# dvs_reva register map
Registers are access not given, no defined reset value unless marked. A register's access mark holds for its fields unless they carry their own. Offsets are from the block's base; lines under a group give offsets from that group; [hi:lo] are bit positions; {n}, {i} and the like mark numbered series; 'fields as' and 'values as' point back to an identical list; <NAME> marks a mode.

## Memory map
0x40004800 DVS size 0x30 — Dynamic Voltage Scaling

## Interrupts
83 DVS — Dynamic Voltage Scaling Interrupt

## DVS — Dynamic Voltage Scaling
Base 0x40004800; register names take the prefix DVS_
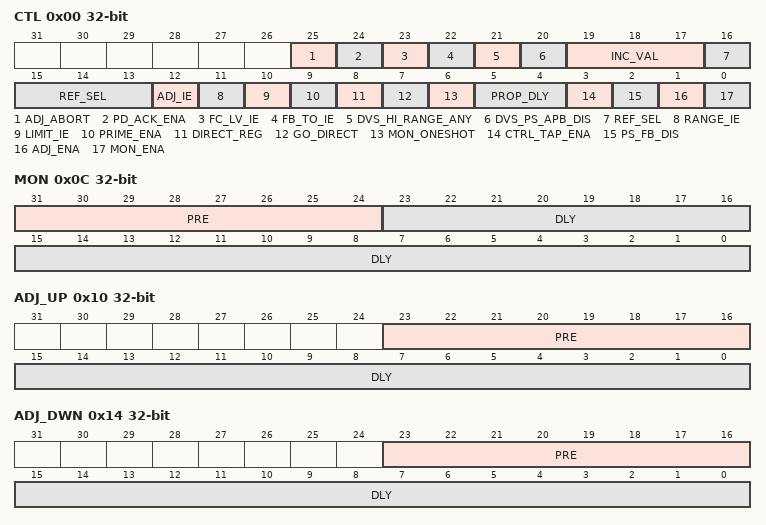
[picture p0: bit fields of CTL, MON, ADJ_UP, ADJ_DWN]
0x00 CTL — Control Register
  [25] ADJ_ABORT — Causes the DVS to enter the idle state immediately on a request to enter a low power mode
  [24] PD_ACK_ENA — Prevent DVS from ack'ing a request to enter a low power mode until in the idle state
  [23] FC_LV_IE — Enable Low Voltage Interrupt
  [22] FB_TO_IE — Enable Voltage Adjustment Timeout Interrupt
  [21] DVS_HI_RANGE_ANY — Any high range signal from a delay line will cause a voltage adjustment
  [20] DVS_PS_APB_DIS — Prevent the application code from adjusting Vcore
  [19:17] INC_VAL — Step size to increment voltage when in automatic mode
  [16:13] REF_SEL — Select TAP used for voltage adjustment
  [12] ADJ_IE — Enable Adjustment Error Interrupt
  [11] RANGE_IE — Enable Range Error Interrupt
  [10] LIMIT_IE — Enable Limit Error Interrupt
  [9] PRIME_ENA — Include a delay line priming signal before monitoring
  [8] DIRECT_REG — Step incrementally to target voltage
  [7] GO_DIRECT — Operate in automatic mode or move directly
  [6] MON_ONESHOT — Measure delay once
  [5:4] PROP_DLY — Additional delay to monitor lines
  [3] CTRL_TAP_ENA — Use the TAP Select for automatic adjustment or monitoring
  [2] PS_FB_DIS — Power Supply Feedback Disable
  [1] ADJ_ENA — Enable the power supply adjustment based on measurements
  [0] MON_ENA — Enable the DVS monitoring circuit
0x04 STAT reset 0x0 — Status Fields
  [31] FC_LV_DET_S — Interrupt flag that mirrors FC_LV_DET_INT
  [30] FC_LV_DET_INT — Interrupt flag that indicates the power supply voltage requested is below the low threshold
  [29] FB_TO_ERR_S — Interrupt flag that mirror FB_TO_ERR and is write one clear
  [28] FB_TO_ERR — Interrupt flag that indicates a timeout while adjusting the voltage
  [27] REF_SEL_ERR — Indicates the ref select register bit is out of range
  [27] REF_SEL_ERR — Indicates the ref select register bit is out of range
  [26] ADJ_ERR — Interrupt flag that indicates up and down adjustment requested simultaneously
  [25] RANGE_ERR — Interrupt flag that indicates a tap has an invalid value
  [24] LIMIT_ERR — Interrupt flag that indicates a voltage count is at/beyond manufacturer limits
  [23] VALID_TAP — At least one delay line has been enabled
  [22] HI_LIMIT_DET — Power supply voltage counter is at high limit
  [21] LO_LIMIT_DET — Power supply voltage counter is at low limit
  [20] ADJ_DLY_OK — Indicates the adjustment delay count is at 0
  [19] MON_DLY_OK — Indicates the monitor delay count is at 0
  [18:12] PS_VCNTR — Voltage Count value sent to the power supply
  [11] PS_IN_RANGE — Indicates if the power supply is in range
  [10] FAST_TRIP_DET — Provides the current combined status of all selected High Range delay lines
  [9] SLOW_TRIP_DET — Provides the current combined status of all selected Low Range delay lines
  [8] CTR_TAP_SEL — Status of selected center tap delay line detect output
  [7] CTR_TAP_OK — Tap Enabled and the Tap is withing Hi/Low limits
  [6] ADJ_ACTIVE — Adjustment to a Direct Voltage
  [5] ADJ_DWN_ENA — DVS Lowering voltage
  [4] ADJ_UP_ENA — DVS Raising voltage
  [3:0] DVS_STATE — State machine state
0x08 DIRECT — Direct control of target voltage
  [6:0] VOLTAGE — Sets the target power supply value
0x0C MON — Monitor Delay
  [31:24] PRE — Number of clocks before DVS_MON_DLY is decremented
  [23:0] DLY — Number of prescaled clocks between delay line samples
0x10 ADJ_UP — Up Delay Register
  [23:16] PRE — Number of clocks before DVS_ADJ_UP_DLY is decremented
  [15:0] DLY — Number of prescaled clocks between updates of the adjustment delay counter
0x14 ADJ_DWN — Down Delay Register
  [23:16] PRE — Number of clocks before DVS_ADJ_DWN_DLY is decremented
  [15:0] DLY — Number of prescaled clocks between updates of the adjustment delay counter
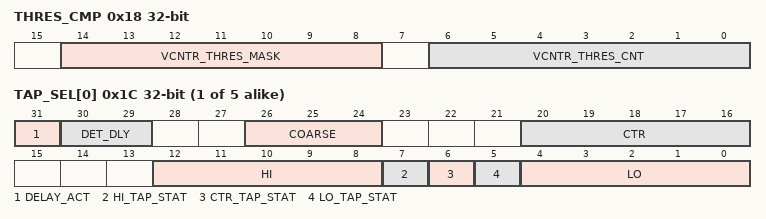
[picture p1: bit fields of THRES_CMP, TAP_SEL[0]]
0x18 THRES_CMP — Up Delay Register
  [14:8] VCNTR_THRES_MASK — Mask applied to threshold and vcount to determine if the device is in a low voltage range
  [6:0] VCNTR_THRES_CNT — Value used to determine 'low voltage' range
{0x1C+5i} TAP_SEL[{i}] (i=0..4) — DVS Tap Select Register
  [31] DELAY_ACT — Set if the delay is active
  [30:29] DET_DLY — Number of HCLK between delay line launch and sampling
  [26:24] COARSE — Selects delay line tap for coarse or fixed delay portion of the line
  [20:16] CTR — Selects delay line tap for center point of auto adjustment
  [12:8] HI — Selects delay line tap for high point of auto adjustment
  [7] HI_TAP_STAT — Returns last delay line tap value
  [6] CTR_TAP_STAT — Returns last delay line tap value
  [5] LO_TAP_STAT — Returns last delay line tap value
  [4:0] LO — Select delay line tap for lower bound of auto adjustment
